# S32K144 register map
Vendor: NXP; Series: S32K; File version: 1.6
CPU: CM4 r0p1, little endian, MPU, FPU, 4 interrupt priority bits
Registers are 32-bit, read-write, reset 0x0 unless marked. A register's access mark holds for its fields unless they carry their own. Offsets are from the block's base; [hi:lo] are bit positions; {n}, {i} and the like mark numbered series.

## SMC — System Mode Controller
Base 0x4007E000; register names take the prefix SMC_
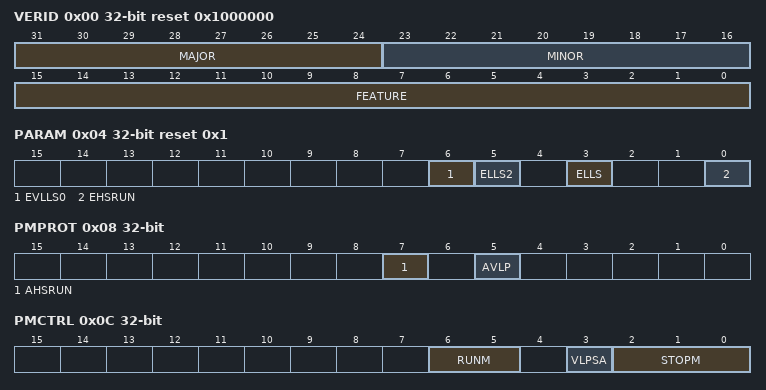
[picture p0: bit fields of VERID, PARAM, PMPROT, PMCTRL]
0x00 VERID ro reset 0x1000000 — SMC Version ID Register
  [31:24] MAJOR — Major Version Number
  [23:16] MINOR — Minor Version Number
  [15:0] FEATURE — Feature Specification Number
    0=Standard features implemented
0x04 PARAM ro reset 0x1 — SMC Parameter Register
  [all] fields
    0=The feature is not available; 1=The feature is available
  [6] EVLLS0 — Existence of VLLS0 feature
  [5] ELLS2 — Existence of LLS2 feature
  [3] ELLS — Existence of LLS feature
  [0] EHSRUN — Existence of HSRUN feature
0x08 PMPROT — Power Mode Protection register
  [7] AHSRUN — Allow High Speed Run mode
    0=HSRUN is not allowed; 1=HSRUN is allowed
  [5] AVLP — Allow Very-Low-Power Modes
    0=VLPR and VLPS are not allowed; 1=VLPR and VLPS are allowed
0x0C PMCTRL — Power Mode Control register
  [6:5] RUNM — Run Mode Control
    0=Normal Run mode (RUN); 2=Very-Low-Power Run mode (VLPR); 3=High Speed Run mode (HSRUN)
  [3] VLPSA ro — Very Low Power Stop Aborted
    0=The previous stop mode entry was successful; 1=The previous stop mode entry was aborted
  [2:0] STOPM — Stop Mode Control
    0=Normal Stop (STOP); 2=Very-Low-Power Stop (VLPS); 6=Reseved
0x10 STOPCTRL reset 0x3 — Stop Control Register
  [7:6] STOPO — Stop Option
    1=STOP1 - Stop with both system and bus clocks disabled; 2=STOP2 - Stop with system clock disabled and bus clock enabled
0x14 PMSTAT ro reset 0x1 — Power Mode Status register
  [7:0] PMSTAT — Power Mode Status

## PTA — General Purpose Input/Output
Base 0x400FF000; register names take the prefix GPIOA_
0x00 PDOR — Port Data Output Register
  [31:0] PDO — Port Data Output
0x04 PSOR wo — Port Set Output Register
  [31:0] PTSO — Port Set Output
0x08 PCOR wo — Port Clear Output Register
  [31:0] PTCO — Port Clear Output
0x0C PTOR wo — Port Toggle Output Register
  [31:0] PTTO — Port Toggle Output
0x10 PDIR ro — Port Data Input Register
  [31:0] PDI — Port Data Input
0x14 PDDR — Port Data Direction Register
  [31:0] PDD — Port Data Direction
0x18 PIDR — Port Input Disable Register
  [31:0] PID — Port Input Disable

## PTB — General Purpose Input/Output
Base 0x400FF040; register names take the prefix GPIOB_
Registers as PTA.

## PTC — General Purpose Input/Output
Base 0x400FF080; register names take the prefix GPIOC_
Registers as PTA; these are added or differ:
0x08 PCOR wo — Port Clear Output Register
  [31:0] PTCO — Port Clear Output

## PTD — General Purpose Input/Output
Base 0x400FF0C0; register names take the prefix GPIOD_
Registers as PTA.

## PTE — General Purpose Input/Output
Base 0x400FF100; register names take the prefix GPIOE_
Registers as PTA.

## S32_SysTick — System timer
Base 0xE000E010; register names take the prefix SYST_
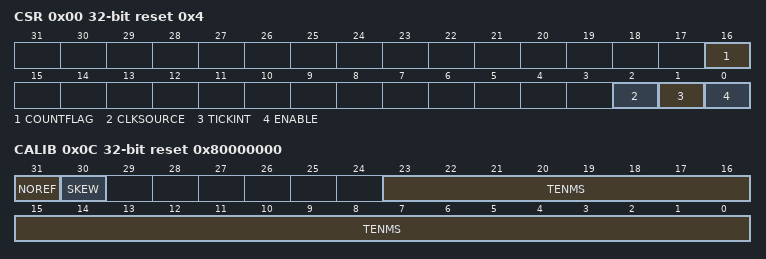
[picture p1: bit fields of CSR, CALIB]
0x00 CSR reset 0x4 — SysTick Control and Status Register
  [16] COUNTFLAG — Returns 1 if timer counted to 0 since last time this was read
  [2] CLKSOURCE — Indicates the clock source
    0=external clock; 1=processor clock
  [1] TICKINT — Enables SysTick exception request
    0=counting down to 0 does not assert the SysTick exception request; 1=counting down to 0 asserts the SysTick exception request
  [0] ENABLE — Enables the counter
    0=counter disabled; 1=counter enabled
0x04 RVR — SysTick Reload Value Register
  [23:0] RELOAD — Value to load into the SysTick Current Value Register when the counter reaches 0
0x08 CVR — SysTick Current Value Register
  [23:0] CURRENT — Current value at the time the register is accessed
0x0C CALIB ro reset 0x80000000 — SysTick Calibration Value Register
  [31] NOREF — Indicates whether the device provides a reference clock to the processor
    0=The reference clock is provided; 1=The reference clock is not provided
  [30] SKEW — Indicates whether the TENMS value is exact
    0=TENMS value is exact; 1=TENMS value is inexact, or not given
  [23:0] TENMS — Reload value to use for 10ms timing

## S32_NVIC — Nested Vectored Interrupt Controller
Base 0xE000E100
{0x0+4i} NVICISER{i} (i=0..7) — Interrupt Set Enable Register n
  [31:0] SETENA — Interrupt set enable bits
{0x80+4i} NVICICER{i} (i=0..7) — Interrupt Clear Enable Register n
  [31:0] CLRENA — Interrupt clear-enable bits
{0x100+4i} NVICISPR{i} (i=0..7) — Interrupt Set Pending Register n
  [31:0] SETPEND — Interrupt set-pending bits
{0x180+4i} NVICICPR{i} (i=0..7) — Interrupt Clear Pending Register n
  [31:0] CLRPEND — Interrupt clear-pending bits
{0x200+4i} NVICIABR{i} (i=0..7) — Interrupt Active bit Register n
  [31:0] ACTIVE — Interrupt active flags
{0x300+i} NVICIP{i} 8-bit (i=0..239) — Interrupt Priority Register n
  [7:0] PRI{i} — Priority of interrupt {i}
0xE00 NVICSTIR wo — Software Trigger Interrupt Register
  [8:0] INTID — Interrupt ID of the interrupt to trigger, in the range 0-239. For example, a value of 0x03 specifies interrupt IRQ3.

## LMEM — Local Memory Controller
Base 0xE0082000; register names take the prefix LMEM_
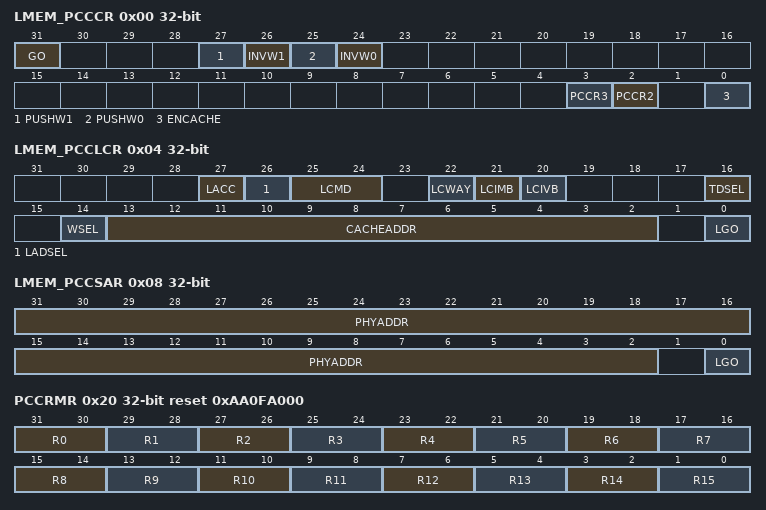
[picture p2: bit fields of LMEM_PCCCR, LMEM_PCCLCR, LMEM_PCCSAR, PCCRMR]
0x00 LMEM_PCCCR — Cache control register
  [31] GO — Initiate Cache Command
    0=Write: no effect. Read: no cache command active.; 1=Write: initiate command indicated by bits 27-24. Read: cache command active.
  [27] PUSHW1 — Push Way 1
    0=No operation; 1=When setting the GO bit, push all modified lines in way 1
  [26] INVW1 — Invalidate Way 1
    0=No operation; 1=When setting the GO bit, invalidate all lines in way 1
  [25] PUSHW0 — Push Way 0
    0=No operation; 1=When setting the GO bit, push all modified lines in way 0
  [24] INVW0 — Invalidate Way 0
    0=No operation; 1=When setting the GO bit, invalidate all lines in way 0
  [3] PCCR3 — Forces no allocation on cache misses (must also have PCCR2 asserted)
  [2] PCCR2 — Forces all cacheable spaces to write through
  [0] ENCACHE — Cache enable
    0=Cache disabled; 1=Cache enabled
0x04 LMEM_PCCLCR — Cache line control register
  [27] LACC — Line access type
    0=Read; 1=Write
  [26] LADSEL — Line Address Select
    0=Cache address; 1=Physical address
  [25:24] LCMD — Line Command
    0=Search and read or write; 1=Invalidate; 2=Push; 3=Clear
  [22] LCWAY — Line Command Way
  [21] LCIMB — Line Command Initial Modified Bit
  [20] LCIVB — Line Command Initial Valid Bit
  [16] TDSEL — Tag/Data Select
    0=Data; 1=Tag
  [14] WSEL — Way select
    0=Way 0; 1=Way 1
  [13:2] CACHEADDR — Cache address
  [0] LGO — Initiate Cache Line Command
    0=Write: no effect. Read: no line command active.; 1=Write: initiate line command indicated by bits 27-24. Read: line command active.
0x08 LMEM_PCCSAR — Cache search address register
  [31:2] PHYADDR — Physical Address
  [0] LGO — Initiate Cache Line Command
    0=Write: no effect. Read: no line command active.; 1=Write: initiate line command indicated by bits CLCR[27:24]. Read: line command active.
0x0C LMEM_PCCCVR — Cache read/write value register
  [31:0] DATA — Cache read/write Data
0x20 PCCRMR reset 0xAA0FA000 — Cache regions mode register
  [all] fields
    0=Non-cacheable; 1=Non-cacheable; 2=Write-through; 3=Write-back
  [31-2n:30-2n] R{n} (n=0..15) — Region {n} mode
